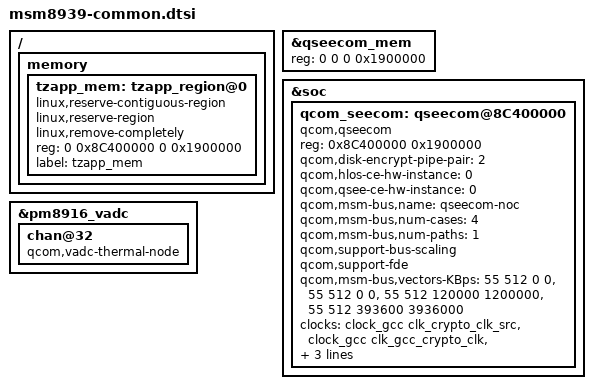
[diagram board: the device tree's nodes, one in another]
/* Copyright (c) 2016, The Linux Foundation. All rights reserved.
 *
 * This program is free software; you can redistribute it and/or modify
 * it under the terms of the GNU General Public License version 2 and
 * only version 2 as published by the Free Software Foundation.
 *
 * This program is distributed in the hope that it will be useful,
 * but WITHOUT ANY WARRANTY; without even the implied warranty of
 * MERCHANTABILITY or FITNESS FOR A PARTICULAR PURPOSE.  See the
 * GNU General Public License for more details.
 */

&qseecom_mem {
	reg = <0 0 0 0x1900000>;
};

/ {
	memory {
		tzapp_mem: tzapp_region@0 {
			linux,reserve-contiguous-region;
			linux,reserve-region;
			linux,remove-completely;
			reg = <0 0x8C400000 0 0x1900000>;
			label = "tzapp_mem";
		};
	};
};

&soc {

	/delete-node/ qseecom@86000000;

	qcom_seecom: qseecom@8C400000 {
		compatible = "qcom,qseecom";
		reg = <0x8C400000 0x1900000>;
		reg-names = "secapp-region";
		qcom,disk-encrypt-pipe-pair = <2>;
		qcom,hlos-ce-hw-instance = <0>;
		qcom,qsee-ce-hw-instance = <0>;
		qcom,msm-bus,name = "qseecom-noc";
		qcom,msm-bus,num-cases = <4>;
		qcom,msm-bus,num-paths = <1>;
		qcom,support-bus-scaling;
		qcom,support-fde;
		qcom,msm-bus,vectors-KBps =
				<55 512 0 0>,
				<55 512 0 0>,
				<55 512 120000 1200000>,
				<55 512 393600 3936000>;
		clocks = <&clock_gcc clk_crypto_clk_src>,
			 <&clock_gcc clk_gcc_crypto_clk>,
			 <&clock_gcc clk_gcc_crypto_ahb_clk>,
			 <&clock_gcc clk_gcc_crypto_axi_clk>;
		clock-names = "core_clk_src", "core_clk",
				"iface_clk", "bus_clk";
		status = "okay";
		qcom,ce-opp-freq = <100000000>;
	};
};

&pm8916_vadc {
	chan@32 {
		qcom,vadc-thermal-node;
	};
};
